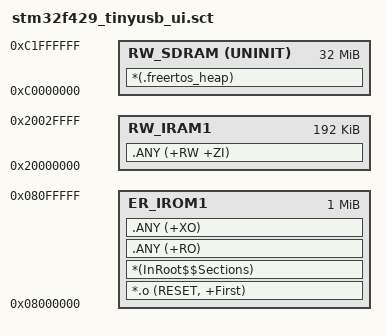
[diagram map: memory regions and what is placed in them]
; *************************************************************
; *** Scatter-Loading Description File for stm32f429_tinyusb_ui (Keil MDK-ARM)
; *** Generated by MDK-ARM/gen_uvision.py - do not edit by hand.
; *** Mirrors sys_startup/STM32F429IGTx_FLASH.ld (GCC build).
; *************************************************************

LR_IROM1 0x08000000 0x00100000  {    ; load region size_region
  ER_IROM1 0x08000000 0x00100000  {  ; load address = execution address
   *.o (RESET, +First)
   *(InRoot$$Sections)
   .ANY (+RO)
   .ANY (+XO)
  }
  ; External SDRAM @ 0xC0000000: FreeRTOS heap_5 region (ucHeap, 512 KB,
  ; app/sdram_heap.c).  UNINIT -> __main does NOT zero/copy it: the
  ; FMC/SDRAM controller is only initialized inside main(), touching
  ; 0xC0000000 earlier would HardFault (NOLOAD in the GCC linker script).
  RW_SDRAM 0xC0000000 0x02000000 UNINIT  {
   *(.freertos_heap)
  }
  RW_IRAM1 0x20000000 0x00030000  {  ; RW data, 192 KB on-chip SRAM
   .ANY (+RW +ZI)
  }
}
